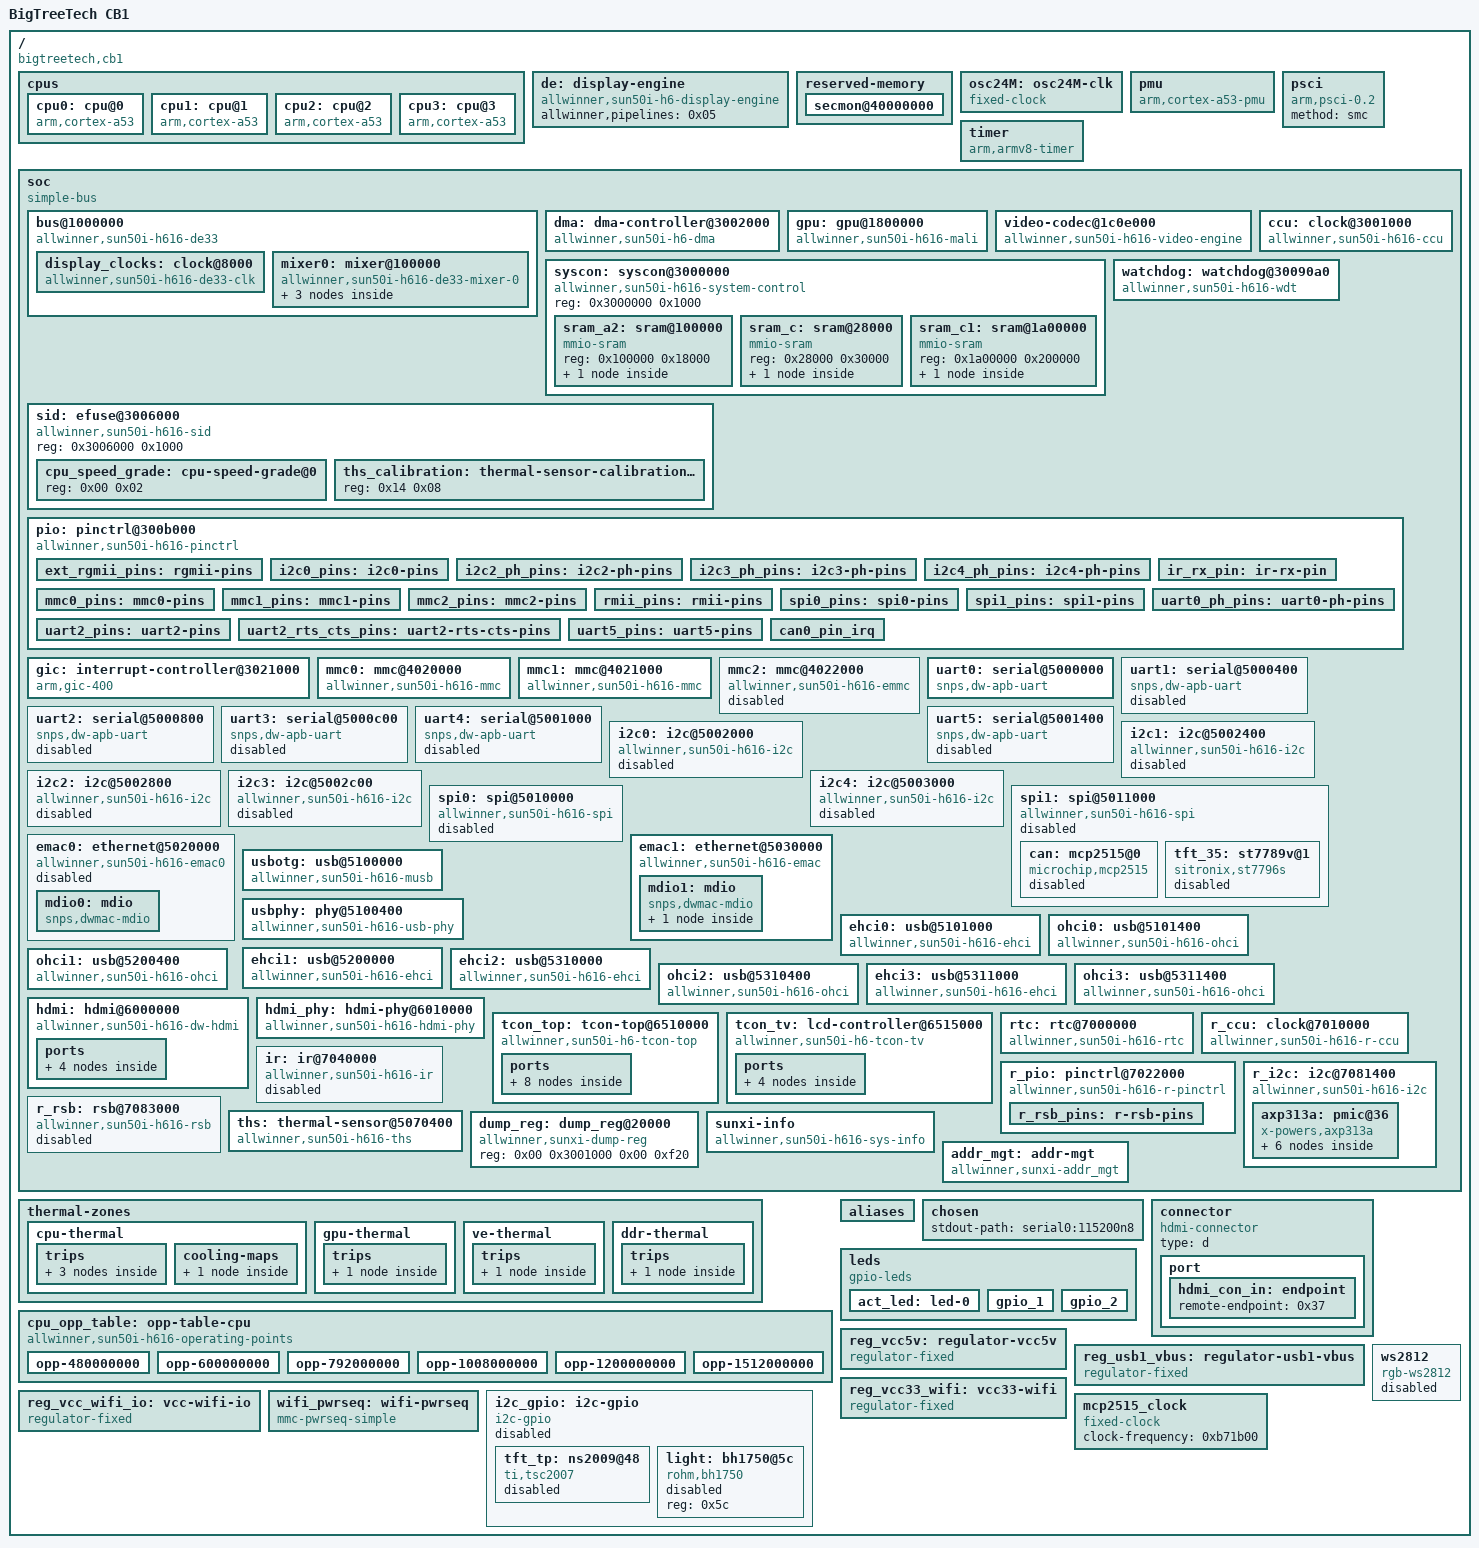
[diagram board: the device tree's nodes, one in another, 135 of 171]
/dts-v1/;

/ {
	interrupt-parent = <0x01>;
	#address-cells = <0x02>;
	#size-cells = <0x02>;
	model = "BigTreeTech CB1";
	compatible = "bigtreetech,cb1", "allwinner,sun50i-h616";

	cpus {
		#address-cells = <0x01>;
		#size-cells = <0x00>;

		cpu0: cpu@0 {
			compatible = "arm,cortex-a53";
			device_type = "cpu";
			reg = <0x00>;
			enable-method = "psci";
			clocks = <0x02 0x15>;
			clock-latency-ns = <0x3b9b0>;
			#cooling-cells = <0x02>;
			operating-points-v2 = <0x03>;
			cpu-supply = <0x04>;
			status = "okay";
			phandle = <0x06>;
		};

		cpu1: cpu@1 {
			compatible = "arm,cortex-a53";
			device_type = "cpu";
			reg = <0x01>;
			enable-method = "psci";
			clocks = <0x02 0x15>;
			clock-latency-ns = <0x3b9b0>;
			#cooling-cells = <0x02>;
			operating-points-v2 = <0x03>;
			phandle = <0x07>;
		};

		cpu2: cpu@2 {
			compatible = "arm,cortex-a53";
			device_type = "cpu";
			reg = <0x02>;
			enable-method = "psci";
			clocks = <0x02 0x15>;
			clock-latency-ns = <0x3b9b0>;
			#cooling-cells = <0x02>;
			operating-points-v2 = <0x03>;
			phandle = <0x08>;
		};

		cpu3: cpu@3 {
			compatible = "arm,cortex-a53";
			device_type = "cpu";
			reg = <0x03>;
			enable-method = "psci";
			clocks = <0x02 0x15>;
			clock-latency-ns = <0x3b9b0>;
			#cooling-cells = <0x02>;
			operating-points-v2 = <0x03>;
			phandle = <0x09>;
		};
	};

	de: display-engine {
		compatible = "allwinner,sun50i-h6-display-engine";
		allwinner,pipelines = <0x05>;
		status = "okay";
	};

	reserved-memory {
		#address-cells = <0x02>;
		#size-cells = <0x02>;
		ranges;

		secmon@40000000 {
			reg = <0x00 0x40000000 0x00 0x80000>;
			no-map;
		};
	};

	osc24M: osc24M-clk {
		#clock-cells = <0x00>;
		compatible = "fixed-clock";
		clock-frequency = <0x16e3600>;
		clock-output-names = "osc24M";
		phandle = <0x0f>;
	};

	pmu {
		compatible = "arm,cortex-a53-pmu";
		interrupts = <0x00 0x8c 0x04>, <0x00 0x8d 0x04>, <0x00 0x8e 0x04>, <0x00 0x8f 0x04>;
		interrupt-affinity = <0x06>, < 0x07>, < 0x08>, < 0x09>;
	};

	psci {
		compatible = "arm,psci-0.2";
		method = "smc";
	};

	timer {
		compatible = "arm,armv8-timer";
		arm,no-tick-in-suspend;
		interrupts = <0x01 0x0d 0xf04>, <0x01 0x0e 0xf04>, <0x01 0x0b 0xf04>, <0x01 0x0a 0xf04>;
	};

	soc {
		compatible = "simple-bus";
		#address-cells = <0x01>;
		#size-cells = <0x01>;
		ranges = <0x00 0x00 0x00 0x40000000>;

		bus@1000000 {
			compatible = "allwinner,sun50i-h616-de33", "allwinner,sun50i-a64-de2";
			reg = <0x1000000 0x400000>;
			allwinner,sram = <0x0a 0x01>;
			#address-cells = <0x01>;
			#size-cells = <0x01>;
			ranges = <0x00 0x1000000 0x400000>;

			display_clocks: clock@8000 {
				compatible = "allwinner,sun50i-h616-de33-clk";
				reg = <0x8000 0x100>;
				clocks = <0x02 0x1d>, < 0x02 0x1e>;
				clock-names = "mod", "bus";
				resets = <0x02 0x01>;
				#clock-cells = <0x01>;
				#reset-cells = <0x01>;
				phandle = <0x0b>;
			};

			mixer0: mixer@100000 {
				compatible = "allwinner,sun50i-h616-de33-mixer-0";
				reg = <0x100000 0x100000>, <0x8100 0x40>, <0x280000 0x20000>;
				clocks = <0x0b 0x00>, < 0x0b 0x06>;
				clock-names = "bus", "mod";
				resets = <0x0b 0x00>;
				phandle = <0x05>;

				ports {
					#address-cells = <0x01>;
					#size-cells = <0x00>;

					mixer0_out: port@1 {
						reg = <0x01>;

						mixer0_out_tcon_top_mixer0: endpoint {
							remote-endpoint = <0x0c>;
							phandle = <0x29>;
						};
					};
				};
			};
		};

		dma: dma-controller@3002000 {
			compatible = "allwinner,sun50i-h6-dma";
			reg = <0x3002000 0x1000>;
			interrupts = <0x00 0x2a 0x04>;
			clocks = <0x02 0x2a>, < 0x02 0x32>;
			clock-names = "bus", "mbus";
			dma-channels = <0x10>;
			dma-requests = <0x31>;
			resets = <0x02 0x06>;
			#dma-cells = <0x01>;
			phandle = <0x1a>;
		};

		gpu: gpu@1800000 {
			compatible = "allwinner,sun50i-h616-mali", "arm,mali-bifrost";
			reg = <0x1800000 0x40000>;
			interrupts = <0x00 0x5f 0x04>, <0x00 0x60 0x04>, <0x00 0x61 0x04>;
			interrupt-names = "job", "mmu", "gpu";
			clocks = <0x02 0x23>, < 0x02 0x24>;
			clock-names = "core", "bus";
			resets = <0x02 0x03>;
			status = "okay";
			mali-supply = <0x0d>;
		};

		video-codec@1c0e000 {
			compatible = "allwinner,sun50i-h616-video-engine";
			reg = <0x1c0e000 0x2000>;
			clocks = <0x02 0x29>, < 0x02 0x28>, < 0x02 0x33>;
			clock-names = "ahb", "mod", "ram";
			resets = <0x02 0x05>;
			interrupts = <0x00 0x5d 0x04>;
			allwinner,sram = <0x0e 0x01>;
		};

		syscon: syscon@3000000 {
			compatible = "allwinner,sun50i-h616-system-control";
			reg = <0x3000000 0x1000>;
			#address-cells = <0x01>;
			#size-cells = <0x01>;
			ranges;
			phandle = <0x20>;

			sram_a2: sram@100000 {
				compatible = "mmio-sram";
				reg = <0x100000 0x18000>;
				#address-cells = <0x01>;
				#size-cells = <0x01>;
				ranges = <0x00 0x100000 0x18000>;

				scpi_sram: scpi-sram@17c00 {
					compatible = "arm,scp-shmem";
					reg = <0x17c00 0x200>;
				};
			};

			sram_c: sram@28000 {
				compatible = "mmio-sram";
				reg = <0x28000 0x30000>;
				#address-cells = <0x01>;
				#size-cells = <0x01>;
				ranges = <0x00 0x28000 0x30000>;

				de3_sram: sram-section@0 {
					compatible = "allwinner,sun50i-h616-sram-c", "allwinner,sun50i-a64-sram-c";
					reg = <0x00 0x1e000>;
					phandle = <0x0a>;
				};
			};

			sram_c1: sram@1a00000 {
				compatible = "mmio-sram";
				reg = <0x1a00000 0x200000>;
				#address-cells = <0x01>;
				#size-cells = <0x01>;
				ranges = <0x00 0x1a00000 0x200000>;

				ve_sram: sram-section@0 {
					compatible = "allwinner,sun50i-h616-sram-c1";
					reg = <0x00 0x200000>;
					phandle = <0x0e>;
				};
			};
		};

		ccu: clock@3001000 {
			compatible = "allwinner,sun50i-h616-ccu";
			reg = <0x3001000 0x1000>;
			clocks = <0x0f>, < 0x10 0x00>, < 0x10 0x02>;
			clock-names = "hosc", "losc", "iosc";
			#clock-cells = <0x01>;
			#reset-cells = <0x01>;
			phandle = <0x02>;
		};

		sid: efuse@3006000 {
			compatible = "allwinner,sun50i-h616-sid";
			reg = <0x3006000 0x1000>;
			#address-cells = <0x01>;
			#size-cells = <0x01>;

			cpu_speed_grade: cpu-speed-grade@0 {
				reg = <0x00 0x02>;
				phandle = <0x36>;
			};

			ths_calibration: thermal-sensor-calibration@14 {
				reg = <0x14 0x08>;
				phandle = <0x33>;
			};
		};

		watchdog: watchdog@30090a0 {
			compatible = "allwinner,sun50i-h616-wdt", "allwinner,sun6i-a31-wdt";
			reg = <0x30090a0 0x20>;
			interrupts = <0x00 0x32 0x04>;
			clocks = <0x0f>;
		};

		pio: pinctrl@300b000 {
			compatible = "allwinner,sun50i-h616-pinctrl";
			reg = <0x300b000 0x400>;
			interrupts = <0x00 0x33 0x04>, <0x00 0x34 0x04>, <0x00 0x35 0x04>, <0x00 0x2b 0x04>, <0x00 0x36 0x04>, <0x00 0x37 0x04>, <0x00 0x38 0x04>, <0x00 0x39 0x04>;
			clocks = <0x02 0x1a>, < 0x0f>, < 0x10 0x00>;
			clock-names = "apb", "hosc", "losc";
			gpio-controller;
			#gpio-cells = <0x03>;
			interrupt-controller;
			#interrupt-cells = <0x03>;
			phandle = <0x1d>;

			ext_rgmii_pins: rgmii-pins {
				pins = "PI0", "PI1", "PI2", "PI3", "PI4", "PI5", "PI7", "PI8", "PI9", "PI10", "PI11", "PI12", "PI13", "PI14", "PI15", "PI16";
				function = "emac0";
				drive-strength = <0x28>;
			};

			i2c0_pins: i2c0-pins {
				pins = "PI6", "PI7";
				function = "i2c0";
				phandle = <0x19>;
			};

			i2c2_ph_pins: i2c2-ph-pins {
				pins = "PH2", "PH3";
				function = "i2c2";
			};

			i2c3_ph_pins: i2c3-ph-pins {
				pins = "PH4", "PH5";
				function = "i2c3";
			};

			i2c4_ph_pins: i2c4-ph-pins {
				pins = "PH6", "PH7";
				function = "i2c4";
			};

			ir_rx_pin: ir-rx-pin {
				pins = "PH10";
				function = "ir_rx";
				phandle = <0x31>;
			};

			mmc0_pins: mmc0-pins {
				pins = "PF0", "PF1", "PF2", "PF3", "PF4", "PF5";
				function = "mmc0";
				drive-strength = <0x1e>;
				bias-pull-up;
				phandle = <0x11>;
			};

			mmc1_pins: mmc1-pins {
				pins = "PG0", "PG1", "PG2", "PG3", "PG4", "PG5";
				function = "mmc1";
				drive-strength = <0x1e>;
				bias-pull-up;
				phandle = <0x13>;
			};

			mmc2_pins: mmc2-pins {
				pins = "PC0", "PC1", "PC5", "PC6", "PC8", "PC9", "PC10", "PC11", "PC13", "PC14", "PC15", "PC16";
				function = "mmc2";
				drive-strength = <0x1e>;
				bias-pull-up;
				phandle = <0x17>;
			};

			rmii_pins: rmii-pins {
				pins = "PA0", "PA1", "PA2", "PA3", "PA4", "PA5", "PA6", "PA7", "PA8", "PA9";
				function = "emac1";
				drive-strength = <0x28>;
				phandle = <0x21>;
			};

			spi0_pins: spi0-pins {
				pins = "PC0", "PC2", "PC4";
				function = "spi0";
				phandle = <0x1b>;
			};

			spi1_pins: spi1-pins {
				pins = "PH6", "PH7", "PH8";
				function = "spi1";
				phandle = <0x1c>;
			};

			uart0_ph_pins: uart0-ph-pins {
				pins = "PH0", "PH1";
				function = "uart0";
				phandle = <0x18>;
			};

			uart2_pins: uart2-pins {
				pins = "PH5", "PH6";
				function = "uart2";
			};

			uart2_rts_cts_pins: uart2-rts-cts-pins {
				pins = "PH7", "PH8";
				function = "uart2";
			};

			uart5_pins: uart5-pins {
				pins = "PH2", "PH3";
				function = "uart5";
			};

			can0_pin_irq: can0_pin_irq {
				function = "irq";
				bias-pull-up;
				pins = "PC9";
				phandle = <0x1f>;
			};
		};

		gic: interrupt-controller@3021000 {
			compatible = "arm,gic-400";
			reg = <0x3021000 0x1000>, <0x3022000 0x2000>, <0x3024000 0x2000>, <0x3026000 0x2000>;
			interrupts = <0x01 0x09 0xf04>;
			interrupt-controller;
			#interrupt-cells = <0x03>;
			phandle = <0x01>;
		};

		mmc0: mmc@4020000 {
			compatible = "allwinner,sun50i-h616-mmc", "allwinner,sun50i-a100-mmc";
			reg = <0x4020000 0x1000>;
			clocks = <0x02 0x3f>, < 0x02 0x3c>;
			clock-names = "ahb", "mmc";
			resets = <0x02 0x0e>;
			reset-names = "ahb";
			interrupts = <0x00 0x23 0x04>;
			pinctrl-names = "default";
			pinctrl-0 = <0x11>;
			status = "okay";
			max-frequency = <0x2faf080>;
			cap-sd-highspeed;
			cap-mmc-highspeed;
			mmc-ddr-3_3v;
			cap-sdio-irq;
			#address-cells = <0x01>;
			#size-cells = <0x00>;
			vmmc-supply = <0x12>;
			broken-cd;
			bus-width = <0x04>;
		};

		mmc1: mmc@4021000 {
			compatible = "allwinner,sun50i-h616-mmc", "allwinner,sun50i-a100-mmc";
			reg = <0x4021000 0x1000>;
			clocks = <0x02 0x40>, < 0x02 0x3d>;
			clock-names = "ahb", "mmc";
			resets = <0x02 0x0f>;
			reset-names = "ahb";
			interrupts = <0x00 0x24 0x04>;
			pinctrl-names = "default";
			pinctrl-0 = <0x13>;
			status = "okay";
			max-frequency = <0x17d7840>;
			cap-sd-highspeed;
			cap-mmc-highspeed;
			mmc-ddr-3_3v;
			cap-sdio-irq;
			#address-cells = <0x01>;
			#size-cells = <0x00>;
			vmmc-supply = <0x14>;
			vqmmc-supply = <0x15>;
			mmc-pwrseq = <0x16>;
			bus-width = <0x04>;
			non-removable;
			mmc-ddr-1_8v;
		};

		mmc2: mmc@4022000 {
			compatible = "allwinner,sun50i-h616-emmc", "allwinner,sun50i-a100-emmc";
			reg = <0x4022000 0x1000>;
			clocks = <0x02 0x41>, < 0x02 0x3e>;
			clock-names = "ahb", "mmc";
			resets = <0x02 0x10>;
			reset-names = "ahb";
			interrupts = <0x00 0x25 0x04>;
			pinctrl-names = "default";
			pinctrl-0 = <0x17>;
			status = "disabled";
			max-frequency = <0x8f0d180>;
			cap-sd-highspeed;
			cap-mmc-highspeed;
			mmc-ddr-3_3v;
			cap-sdio-irq;
			#address-cells = <0x01>;
			#size-cells = <0x00>;
		};

		uart0: serial@5000000 {
			compatible = "snps,dw-apb-uart";
			reg = <0x5000000 0x400>;
			interrupts = <0x00 0x00 0x04>;
			reg-shift = <0x02>;
			reg-io-width = <0x04>;
			clocks = <0x02 0x42>;
			resets = <0x02 0x11>;
			status = "okay";
			pinctrl-names = "default";
			pinctrl-0 = <0x18>;
		};

		uart1: serial@5000400 {
			compatible = "snps,dw-apb-uart";
			reg = <0x5000400 0x400>;
			interrupts = <0x00 0x01 0x04>;
			reg-shift = <0x02>;
			reg-io-width = <0x04>;
			clocks = <0x02 0x43>;
			resets = <0x02 0x12>;
			status = "disabled";
		};

		uart2: serial@5000800 {
			compatible = "snps,dw-apb-uart";
			reg = <0x5000800 0x400>;
			interrupts = <0x00 0x02 0x04>;
			reg-shift = <0x02>;
			reg-io-width = <0x04>;
			clocks = <0x02 0x44>;
			resets = <0x02 0x13>;
			status = "disabled";
		};

		uart3: serial@5000c00 {
			compatible = "snps,dw-apb-uart";
			reg = <0x5000c00 0x400>;
			interrupts = <0x00 0x03 0x04>;
			reg-shift = <0x02>;
			reg-io-width = <0x04>;
			clocks = <0x02 0x45>;
			resets = <0x02 0x14>;
			status = "disabled";
		};

		uart4: serial@5001000 {
			compatible = "snps,dw-apb-uart";
			reg = <0x5001000 0x400>;
			interrupts = <0x00 0x04 0x04>;
			reg-shift = <0x02>;
			reg-io-width = <0x04>;
			clocks = <0x02 0x46>;
			resets = <0x02 0x15>;
			status = "disabled";
		};

		uart5: serial@5001400 {
			compatible = "snps,dw-apb-uart";
			reg = <0x5001400 0x400>;
			interrupts = <0x00 0x05 0x04>;
			reg-shift = <0x02>;
			reg-io-width = <0x04>;
			clocks = <0x02 0x47>;
			resets = <0x02 0x16>;
			status = "disabled";
		};

		i2c0: i2c@5002000 {
			compatible = "allwinner,sun50i-h616-i2c", "allwinner,sun8i-v536-i2c", "allwinner,sun6i-a31-i2c";
			reg = <0x5002000 0x400>;
			interrupts = <0x00 0x06 0x04>;
			clocks = <0x02 0x48>;
			resets = <0x02 0x17>;
			pinctrl-names = "default";
			pinctrl-0 = <0x19>;
			status = "disabled";
			#address-cells = <0x01>;
			#size-cells = <0x00>;
		};

		i2c1: i2c@5002400 {
			compatible = "allwinner,sun50i-h616-i2c", "allwinner,sun8i-v536-i2c", "allwinner,sun6i-a31-i2c";
			reg = <0x5002400 0x400>;
			interrupts = <0x00 0x07 0x04>;
			clocks = <0x02 0x49>;
			resets = <0x02 0x18>;
			status = "disabled";
			#address-cells = <0x01>;
			#size-cells = <0x00>;
		};

		i2c2: i2c@5002800 {
			compatible = "allwinner,sun50i-h616-i2c", "allwinner,sun8i-v536-i2c", "allwinner,sun6i-a31-i2c";
			reg = <0x5002800 0x400>;
			interrupts = <0x00 0x08 0x04>;
			clocks = <0x02 0x4a>;
			resets = <0x02 0x19>;
			status = "disabled";
			#address-cells = <0x01>;
			#size-cells = <0x00>;
		};

		i2c3: i2c@5002c00 {
			compatible = "allwinner,sun50i-h616-i2c", "allwinner,sun8i-v536-i2c", "allwinner,sun6i-a31-i2c";
			reg = <0x5002c00 0x400>;
			interrupts = <0x00 0x09 0x04>;
			clocks = <0x02 0x4b>;
			resets = <0x02 0x1a>;
			status = "disabled";
			#address-cells = <0x01>;
			#size-cells = <0x00>;
		};

		i2c4: i2c@5003000 {
			compatible = "allwinner,sun50i-h616-i2c", "allwinner,sun8i-v536-i2c", "allwinner,sun6i-a31-i2c";
			reg = <0x5003000 0x400>;
			interrupts = <0x00 0x0a 0x04>;
			clocks = <0x02 0x4c>;
			resets = <0x02 0x1b>;
			status = "disabled";
			#address-cells = <0x01>;
			#size-cells = <0x00>;
		};

		spi0: spi@5010000 {
			compatible = "allwinner,sun50i-h616-spi", "allwinner,sun8i-h3-spi";
			reg = <0x5010000 0x1000>;
			interrupts = <0x00 0x0c 0x04>;
			clocks = <0x02 0x4f>, < 0x02 0x4d>;
			clock-names = "ahb", "mod";
			dmas = <0x1a 0x16>, < 0x1a 0x16>;
			dma-names = "rx", "tx";
			resets = <0x02 0x1c>;
			pinctrl-names = "default";
			pinctrl-0 = <0x1b>;
			status = "disabled";
			#address-cells = <0x01>;
			#size-cells = <0x00>;
		};

		spi1: spi@5011000 {
			compatible = "allwinner,sun50i-h616-spi", "allwinner,sun8i-h3-spi";
			reg = <0x5011000 0x1000>;
			interrupts = <0x00 0x0d 0x04>;
			clocks = <0x02 0x50>, < 0x02 0x4e>;
			clock-names = "ahb", "mod";
			dmas = <0x1a 0x17>, < 0x1a 0x17>;
			dma-names = "rx", "tx";
			resets = <0x02 0x1d>;
			pinctrl-names = "default";
			pinctrl-0 = <0x1c>;
			status = "disabled";
			#address-cells = <0x01>;
			#size-cells = <0x00>;
			cs-gpios = <0x1d 0x02 0x0b 0x00>, < 0x1d 0x02 0x07 0x00>, < 0x1d 0x02 0x0d 0x00>;

			can: mcp2515@0 {
				status = "disabled";
				compatible = "microchip,mcp2515";
				reg = <0x00>;
				clocks = <0x1e>;
				spi-max-frequency = <0xbebc20>;
				pinctrl-names = "default";
				pinctrl-0 = <0x1f>;
				interrupt-parent = <0x1d>;
				vdd-supply = <0x14>;
				xceiver-supply = <0x14>;
				interrupts = <0x02 0x09 0x08>;
			};

			tft_35: st7789v@1 {
				status = "disabled";
				compatible = "sitronix,st7796s";
				reg = <0x01>;
				spi-max-frequency = <0xbebc20>;
				fps = <0x3c>;
				buswidth = <0x08>;
				rotate = <0x00>;
				width = <0x1e0>;
				height = <0x140>;
				bpp = <0x18>;
				bgr;
				regwidth = <0x08>;
				debug = <0x00>;
				txbuflen = <0x4b000>;
				spi-cpol;
				spi-cpha;
				dc-gpios = <0x1d 0x02 0x0e 0x00>;
			};
		};

		emac0: ethernet@5020000 {
			compatible = "allwinner,sun50i-h616-emac0", "allwinner,sun50i-a64-emac";
			reg = <0x5020000 0x10000>;
			interrupts = <0x00 0x0e 0x04>;
			interrupt-names = "macirq";
			clocks = <0x02 0x52>;
			clock-names = "stmmaceth";
			resets = <0x02 0x1e>;
			reset-names = "stmmaceth";
			syscon = <0x20>;
			status = "disabled";

			mdio0: mdio {
				compatible = "snps,dwmac-mdio";
				#address-cells = <0x01>;
				#size-cells = <0x00>;
			};
		};

		emac1: ethernet@5030000 {
			compatible = "allwinner,sun50i-h616-emac";
			syscon = <0x20 0x01>;
			reg = <0x5030000 0x10000>;
			interrupts = <0x00 0x0f 0x04>;
			interrupt-names = "macirq";
			resets = <0x02 0x1f>;
			reset-names = "stmmaceth";
			clocks = <0x02 0x53>;
			clock-names = "stmmaceth";
			status = "okay";
			pinctrl-names = "default";
			pinctrl-0 = <0x21>;
			phy-mode = "rmii";
			phy-handle = <0x22>;
			phy-supply = <0x12>;
			allwinner,rx-delay-ps = <0xc1c>;
			allwinner,tx-delay-ps = <0x2bc>;

			mdio1: mdio {
				compatible = "snps,dwmac-mdio";
				#address-cells = <0x01>;
				#size-cells = <0x00>;

				rmii_phy: ethernet-phy@1 {
					compatible = "ethernet-phy-ieee802.3-c22";
					reg = <0x01>;
					phandle = <0x22>;
				};
			};
		};

		usbotg: usb@5100000 {
			compatible = "allwinner,sun50i-h616-musb", "allwinner,sun8i-h3-musb";
			reg = <0x5100000 0x400>;
			clocks = <0x02 0x70>;
			resets = <0x02 0x32>;
			interrupts = <0x00 0x19 0x04>;
			interrupt-names = "mc";
			phys = <0x23 0x00>;
			phy-names = "usb";
			extcon = <0x23 0x00>;
			status = "okay";
			dr_mode = "peripheral";
		};

		usbphy: phy@5100400 {
			compatible = "allwinner,sun50i-h616-usb-phy";
			reg = <0x5100400 0x24>, <0x5101800 0x14>, <0x5200800 0x14>, <0x5310800 0x14>, <0x5311800 0x14>;
			reg-names = "phy_ctrl", "pmu0", "pmu1", "pmu2", "pmu3";
			clocks = <0x02 0x61>, < 0x02 0x63>, < 0x02 0x65>, < 0x02 0x67>, < 0x02 0x6e>;
			clock-names = "usb0_phy", "usb1_phy", "usb2_phy", "usb3_phy", "pmu2_clk";
			resets = <0x02 0x26>, < 0x02 0x27>, < 0x02 0x28>, < 0x02 0x29>;
			reset-names = "usb0_reset", "usb1_reset", "usb2_reset", "usb3_reset";
			status = "okay";
			#phy-cells = <0x01>;
			usb1_vbus-supply = <0x24>;
			phandle = <0x23>;
		};

		ehci0: usb@5101000 {
			compatible = "allwinner,sun50i-h616-ehci", "generic-ehci";
			reg = <0x5101000 0x100>;
			interrupts = <0x00 0x1a 0x04>;
			clocks = <0x02 0x68>, < 0x02 0x6c>, < 0x02 0x60>;
			resets = <0x02 0x2a>, < 0x02 0x2e>;
			phys = <0x23 0x00>;
			phy-names = "usb";
			status = "okay";
		};

		ohci0: usb@5101400 {
			compatible = "allwinner,sun50i-h616-ohci", "generic-ohci";
			reg = <0x5101400 0x100>;
			interrupts = <0x00 0x1b 0x04>;
			clocks = <0x02 0x68>, < 0x02 0x60>;
			resets = <0x02 0x2a>;
			phys = <0x23 0x00>;
			phy-names = "usb";
			status = "okay";
		};

		ehci1: usb@5200000 {
			compatible = "allwinner,sun50i-h616-ehci", "generic-ehci";
			reg = <0x5200000 0x100>;
			interrupts = <0x00 0x1c 0x04>;
			clocks = <0x02 0x69>, < 0x02 0x6d>, < 0x02 0x62>;
			resets = <0x02 0x2b>, < 0x02 0x2f>;
			phys = <0x23 0x01>;
			phy-names = "usb";
			status = "okay";
		};

		ohci1: usb@5200400 {
			compatible = "allwinner,sun50i-h616-ohci", "generic-ohci";
			reg = <0x5200400 0x100>;
			interrupts = <0x00 0x1d 0x04>;
			clocks = <0x02 0x69>, < 0x02 0x62>;
			resets = <0x02 0x2b>;
			phys = <0x23 0x01>;
			phy-names = "usb";
			status = "okay";
		};

		ehci2: usb@5310000 {
			compatible = "allwinner,sun50i-h616-ehci", "generic-ehci";
			reg = <0x5310000 0x100>;
			interrupts = <0x00 0x1e 0x04>;
			clocks = <0x02 0x6a>, < 0x02 0x6e>, < 0x02 0x64>;
			resets = <0x02 0x2c>, < 0x02 0x30>;
			phys = <0x23 0x02>;
			phy-names = "usb";
			status = "okay";
		};

		ohci2: usb@5310400 {
			compatible = "allwinner,sun50i-h616-ohci", "generic-ohci";
			reg = <0x5310400 0x100>;
			interrupts = <0x00 0x1f 0x04>;
			clocks = <0x02 0x6a>, < 0x02 0x64>;
			resets = <0x02 0x2c>;
			phys = <0x23 0x02>;
			phy-names = "usb";
			status = "okay";
		};

		ehci3: usb@5311000 {
			compatible = "allwinner,sun50i-h616-ehci", "generic-ehci";
			reg = <0x5311000 0x100>;
			interrupts = <0x00 0x20 0x04>;
			clocks = <0x02 0x6b>, < 0x02 0x6f>, < 0x02 0x66>;
			resets = <0x02 0x2d>, < 0x02 0x31>;
			phys = <0x23 0x03>;
			phy-names = "usb";
			status = "okay";
		};

		ohci3: usb@5311400 {
			compatible = "allwinner,sun50i-h616-ohci", "generic-ohci";
			reg = <0x5311400 0x100>;
			interrupts = <0x00 0x21 0x04>;
			clocks = <0x02 0x6b>, < 0x02 0x66>;
			resets = <0x02 0x2d>;
			phys = <0x23 0x03>;
			phy-names = "usb";
			status = "okay";
		};

		hdmi: hdmi@6000000 {
			#sound-dai-cells = <0x00>;
			compatible = "allwinner,sun50i-h616-dw-hdmi", "allwinner,sun50i-h6-dw-hdmi";
			reg = <0x6000000 0x10000>;
			reg-io-width = <0x01>;
			interrupts = <0x00 0x3f 0x04>;
			clocks = <0x02 0x75>, < 0x02 0x73>, < 0x02 0x72>, < 0x02 0x74>, < 0x02 0x7e>, < 0x02 0x7f>;
			clock-names = "iahb", "isfr", "tmds", "cec", "hdcp", "hdcp-bus";
			resets = <0x02 0x33>, < 0x02 0x3a>;
			reset-names = "ctrl", "hdcp";
			phys = <0x25>;
			phy-names = "phy";
			status = "okay";
			hvcc-supply = <0x26>;

			ports {
				#address-cells = <0x01>;
				#size-cells = <0x00>;

				hdmi_in: port@0 {
					reg = <0x00>;

					hdmi_in_tcon_top: endpoint {
						remote-endpoint = <0x27>;
						phandle = <0x2c>;
					};
				};

				hdmi_out: port@1 {
					reg = <0x01>;

					hdmi_out_con: endpoint {
						remote-endpoint = <0x28>;
						phandle = <0x37>;
					};
				};
			};
		};

		hdmi_phy: hdmi-phy@6010000 {
			compatible = "allwinner,sun50i-h616-hdmi-phy";
			reg = <0x6010000 0x10000>;
			clocks = <0x02 0x75>, < 0x02 0x73>;
			clock-names = "bus", "mod";
			resets = <0x02 0x34>;
			reset-names = "phy";
			#phy-cells = <0x00>;
			phandle = <0x25>;
		};

		tcon_top: tcon-top@6510000 {
			compatible = "allwinner,sun50i-h6-tcon-top";
			reg = <0x6510000 0x1000>;
			clocks = <0x02 0x76>, < 0x02 0x77>;
			clock-names = "bus", "tcon-tv0";
			clock-output-names = "tcon-top-tv0";
			resets = <0x02 0x35>;
			#clock-cells = <0x01>;
			phandle = <0x2d>;

			ports {
				#address-cells = <0x01>;
				#size-cells = <0x00>;

				tcon_top_mixer0_in: port@0 {
					#address-cells = <0x01>;
					#size-cells = <0x00>;
					reg = <0x00>;

					tcon_top_mixer0_in_mixer0: endpoint@0 {
						reg = <0x00>;
						remote-endpoint = <0x29>;
						phandle = <0x0c>;
					};
				};

				tcon_top_mixer0_out: port@1 {
					#address-cells = <0x01>;
					#size-cells = <0x00>;
					reg = <0x01>;

					tcon_top_mixer0_out_tcon_tv: endpoint@2 {
						reg = <0x02>;
						remote-endpoint = <0x2a>;
						phandle = <0x2e>;
					};
				};

				tcon_top_hdmi_in: port@4 {
					#address-cells = <0x01>;
					#size-cells = <0x00>;
					reg = <0x04>;

					tcon_top_hdmi_in_tcon_tv: endpoint@0 {
						reg = <0x00>;
						remote-endpoint = <0x2b>;
						phandle = <0x2f>;
					};
				};

				tcon_top_hdmi_out: port@5 {
					reg = <0x05>;

					tcon_top_hdmi_out_hdmi: endpoint {
						remote-endpoint = <0x2c>;
						phandle = <0x27>;
					};
				};
			};
		};

		tcon_tv: lcd-controller@6515000 {
			compatible = "allwinner,sun50i-h6-tcon-tv", "allwinner,sun8i-r40-tcon-tv";
			reg = <0x6515000 0x1000>;
			interrupts = <0x00 0x42 0x04>;
			clocks = <0x02 0x79>, < 0x2d 0x00>;
			clock-names = "ahb", "tcon-ch1";
			resets = <0x02 0x36>;
			reset-names = "lcd";

			ports {
				#address-cells = <0x01>;
				#size-cells = <0x00>;

				tcon_tv_in: port@0 {
					reg = <0x00>;

					tcon_tv_in_tcon_top_mixer0: endpoint {
						remote-endpoint = <0x2e>;
						phandle = <0x2a>;
					};
				};

				tcon_tv_out: port@1 {
					#address-cells = <0x01>;
					#size-cells = <0x00>;
					reg = <0x01>;

					tcon_tv_out_tcon_top: endpoint@1 {
						reg = <0x01>;
						remote-endpoint = <0x2f>;
						phandle = <0x2b>;
					};
				};
			};
		};

		rtc: rtc@7000000 {
			compatible = "allwinner,sun50i-h616-rtc";
			reg = <0x7000000 0x400>;
			interrupts = <0x00 0x68 0x04>;
			clocks = <0x30 0x0e>, < 0x0f>, < 0x02 0x80>;
			clock-names = "bus", "hosc", "pll-32k";
			#clock-cells = <0x01>;
			phandle = <0x10>;
		};

		r_ccu: clock@7010000 {
			compatible = "allwinner,sun50i-h616-r-ccu";
			reg = <0x7010000 0x210>;
			clocks = <0x0f>, < 0x10 0x00>, < 0x10 0x02>, < 0x02 0x04>;
			clock-names = "hosc", "losc", "iosc", "pll-periph";
			#clock-cells = <0x01>;
			#reset-cells = <0x01>;
			phandle = <0x30>;
		};

		r_pio: pinctrl@7022000 {
			compatible = "allwinner,sun50i-h616-r-pinctrl";
			reg = <0x7022000 0x400>;
			interrupts = <0x00 0x8f 0x04>;
			clocks = <0x30 0x02>, < 0x0f>, < 0x10 0x00>;
			clock-names = "apb", "hosc", "losc";
			gpio-controller;
			#gpio-cells = <0x03>;
			interrupt-controller;
			#interrupt-cells = <0x03>;

			r_rsb_pins: r-rsb-pins {
				pins = "PL0", "PL1";
				function = "s_rsb";
				phandle = <0x32>;
			};
		};

		ir: ir@7040000 {
			compatible = "allwinner,sun50i-h616-ir", "allwinner,sun6i-a31-ir";
			reg = <0x7040000 0x400>;
			interrupts = <0x00 0x6a 0x04>;
			clocks = <0x30 0x09>, < 0x30 0x0b>;
			clock-names = "apb", "ir";
			resets = <0x30 0x05>;
			pinctrl-names = "default";
			pinctrl-0 = <0x31>;
			status = "disabled";
		};

		r_i2c: i2c@7081400 {
			compatible = "allwinner,sun50i-h616-i2c", "allwinner,sun8i-v536-i2c", "allwinner,sun6i-a31-i2c";
			reg = <0x7081400 0x400>;
			interrupts = <0x00 0x69 0x04>;
			clocks = <0x30 0x08>;
			resets = <0x30 0x04>;
			status = "okay";
			#address-cells = <0x01>;
			#size-cells = <0x00>;

			axp313a: pmic@36 {
				compatible = "x-powers,axp313a";
				reg = <0x36>;
				wakeup-source;

				regulators {

					reg_dcdc1: dcdc1 {
						regulator-name = "axp313a-dcdc1";
						regulator-min-microvolt = <0x7a120>;
						regulator-max-microvolt = <0x33e140>;
						regulator-step-delay-us = <0x19>;
						regulator-final-delay-us = <0x32>;
						regulator-always-on;
					};

					reg_dcdc2: dcdc2 {
						regulator-name = "axp313a-dcdc2";
						regulator-min-microvolt = <0x7a120>;
						regulator-max-microvolt = <0x177fa0>;
						regulator-step-delay-us = <0x19>;
						regulator-final-delay-us = <0x32>;
						regulator-ramp-delay = <0xc8>;
						regulator-always-on;
						phandle = <0x04>;
					};

					reg_dcdc3: dcdc3 {
						regulator-name = "axp313a-dcdc3";
						regulator-min-microvolt = <0x7a120>;
						regulator-max-microvolt = <0x1c1380>;
						regulator-step-delay-us = <0x19>;
						regulator-final-delay-us = <0x32>;
						regulator-always-on;
						phandle = <0x0d>;
					};

					reg_aldo1: aldo1 {
						regulator-name = "axp313a-aldo1";
						regulator-min-microvolt = <0x1b7740>;
						regulator-max-microvolt = <0x1b7740>;
						regulator-step-delay-us = <0x19>;
						regulator-final-delay-us = <0x32>;
						regulator-always-on;
						phandle = <0x26>;
					};

					reg_dldo1: dldo1 {
						regulator-name = "axp313a-dldo1";
						regulator-min-microvolt = <0x325aa0>;
						regulator-max-microvolt = <0x325aa0>;
						regulator-step-delay-us = <0x19>;
						regulator-final-delay-us = <0x32>;
						regulator-always-on;
						phandle = <0x12>;
					};
				};
			};
		};

		r_rsb: rsb@7083000 {
			compatible = "allwinner,sun50i-h616-rsb", "allwinner,sun8i-a23-rsb";
			reg = <0x7083000 0x400>;
			interrupts = <0x00 0x6d 0x04>;
			clocks = <0x30 0x0d>;
			clock-frequency = <0x2dc6c0>;
			resets = <0x30 0x07>;
			pinctrl-names = "default";
			pinctrl-0 = <0x32>;
			status = "disabled";
			#address-cells = <0x01>;
			#size-cells = <0x00>;
		};

		ths: thermal-sensor@5070400 {
			compatible = "allwinner,sun50i-h616-ths";
			reg = <0x5070400 0x400>;
			interrupts = <0x00 0x13 0x04>;
			clocks = <0x02 0x56>;
			clock-names = "bus";
			resets = <0x02 0x21>;
			nvmem-cells = <0x33>;
			nvmem-cell-names = "calibration";
			#thermal-sensor-cells = <0x01>;
			phandle = <0x34>;
		};

		dump_reg: dump_reg@20000 {
			compatible = "allwinner,sunxi-dump-reg";
			reg = <0x00 0x3001000 0x00 0xf20>;
			status = "okay";
		};

		sunxi-info {
			compatible = "allwinner,sun50i-h616-sys-info";
			status = "okay";
		};

		addr_mgt: addr-mgt {
			compatible = "allwinner,sunxi-addr_mgt";
			type_addr_wifi = <0x02>;
			type_addr_bt = <0x02>;
			type_addr_eth = <0x02>;
			status = "okay";
		};
	};

	thermal-zones {

		cpu-thermal {
			polling-delay-passive = <0x1f4>;
			polling-delay = <0x3e8>;
			thermal-sensors = <0x34 0x02>;
			sustainable-power = <0x3e8>;
			k_po = <0x14>;
			k_pu = <0x28>;
			k_i = <0x00>;

			trips {

				cpu_threshold: trip-point@0 {
					temperature = <0xea60>;
					type = "passive";
					hysteresis = <0x00>;
				};

				cpu_target: trip-point@1 {
					temperature = <0x11170>;
					type = "passive";
					hysteresis = <0x00>;
					phandle = <0x35>;
				};

				cpu_temp_critical: trip-point@2 {
					temperature = <0x1adb0>;
					type = "critical";
					hysteresis = <0x00>;
				};
			};

			cooling-maps {

				map0 {
					trip = <0x35>;
					cooling-device = <0x06 0xffffffff 0xffffffff>, < 0x07 0xffffffff 0xffffffff>, < 0x08 0xffffffff 0xffffffff>, < 0x09 0xffffffff 0xffffffff>;
				};
			};
		};

		gpu-thermal {
			polling-delay-passive = <0x1f4>;
			polling-delay = <0x3e8>;
			thermal-sensors = <0x34 0x00>;
			sustainable-power = <0x44c>;

			trips {

				gpu_temp_critical: trip-point@0 {
					temperature = <0x1adb0>;
					type = "critical";
					hysteresis = <0x00>;
				};
			};
		};

		ve-thermal {
			polling-delay-passive = <0x00>;
			polling-delay = <0x00>;
			thermal-sensors = <0x34 0x01>;

			trips {

				ve_temp_critical: trip-point@0 {
					temperature = <0x1adb0>;
					type = "critical";
					hysteresis = <0x00>;
				};
			};
		};

		ddr-thermal {
			polling-delay-passive = <0x00>;
			polling-delay = <0x00>;
			thermal-sensors = <0x34 0x03>;

			trips {

				ddr_temp_critical: trip-point@0 {
					temperature = <0x1adb0>;
					type = "critical";
					hysteresis = <0x00>;
				};
			};
		};
	};

	cpu_opp_table: opp-table-cpu {
		compatible = "allwinner,sun50i-h616-operating-points";
		nvmem-cells = <0x36>;
		opp-shared;
		phandle = <0x03>;

		opp-480000000 {
			clock-latency-ns = <0x3b9b0>;
			opp-hz = /bits/ 64 <0x1c9c3800>;
			opp-microvolt-speed0 = <0xc8320 0xc8320 0x10c8e0>;
			opp-microvolt-speed1 = <0xd6d80 0xd6d80 0x10c8e0>;
			opp-microvolt-speed2 = <0xd6d80 0xd6d80 0x10c8e0>;
		};

		opp-600000000 {
			clock-latency-ns = <0x3b9b0>;
			opp-hz = /bits/ 64 <0x23c34600>;
			opp-microvolt-speed0 = <0xc8320 0xc8320 0x10c8e0>;
			opp-microvolt-speed1 = <0xd6d80 0xd6d80 0x10c8e0>;
			opp-microvolt-speed2 = <0xd6d80 0xd6d80 0x10c8e0>;
		};

		opp-792000000 {
			clock-latency-ns = <0x3b9b0>;
			opp-hz = /bits/ 64 <0x2f34f600>;
			opp-microvolt-speed0 = <0xd1f60 0xd1f60 0x10c8e0>;
			opp-microvolt-speed1 = <0xe57e0 0xe57e0 0x10c8e0>;
			opp-microvolt-speed2 = <0xe57e0 0xe57e0 0x10c8e0>;
		};

		opp-1008000000 {
			clock-latency-ns = <0x3b9b0>;
			opp-hz = /bits/ 64 <0x3c14dc00>;
			opp-microvolt-speed0 = <0xdbba0 0xdbba0 0x10c8e0>;
			opp-microvolt-speed1 = <0xf9060 0xf9060 0x10c8e0>;
			opp-microvolt-speed2 = <0xf9060 0xf9060 0x10c8e0>;
		};

		opp-1200000000 {
			clock-latency-ns = <0x3b9b0>;
			opp-hz = /bits/ 64 <0x47868c00>;
			opp-microvolt-speed0 = <0xea600 0xea600 0x10c8e0>;
			opp-microvolt-speed1 = <0x10c8e0 0x10c8e0 0x10c8e0>;
			opp-microvolt-speed2 = <0x10c8e0 0x10c8e0 0x10c8e0>;
		};

		opp-1512000000 {
			clock-latency-ns = <0x3b9b0>;
			opp-hz = /bits/ 64 <0x5a1f4a00>;
			opp-microvolt-speed0 = <0x10c8e0 0x10c8e0 0x10c8e0>;
			opp-microvolt-speed1 = <0x10c8e0 0x10c8e0 0x10c8e0>;
			opp-microvolt-speed2 = <0x10c8e0 0x10c8e0 0x10c8e0>;
		};
	};

	aliases {
		ethernet0 = "/soc/ethernet@5030000";
		serial0 = "/soc/serial@5000000";
	};

	chosen {
		stdout-path = "serial0:115200n8";
	};

	connector {
		compatible = "hdmi-connector";
		type = "d";

		port {

			hdmi_con_in: endpoint {
				remote-endpoint = <0x37>;
				phandle = <0x28>;
			};
		};
	};

	leds {
		compatible = "gpio-leds";

		act_led: led-0 {
			gpios = <0x1d 0x07 0x05 0x01>;
			linux,default-trigger = "heartbeat";
		};

		gpio_1 {
			function = "wifi_power";
			gpios = <0x1d 0x05 0x06 0x00>;
			default-state = "on";
		};

		gpio_2 {
			function = "wifi_wake";
			gpios = <0x1d 0x06 0x0f 0x00>;
			default-state = "on";
		};
	};

	reg_vcc5v: regulator-vcc5v {
		compatible = "regulator-fixed";
		regulator-name = "vcc-5v";
		regulator-min-microvolt = <0x4c4b40>;
		regulator-max-microvolt = <0x4c4b40>;
		regulator-always-on;
		phandle = <0x38>;
	};

	reg_usb1_vbus: regulator-usb1-vbus {
		compatible = "regulator-fixed";
		regulator-name = "usb1-vbus";
		regulator-min-microvolt = <0x4c4b40>;
		regulator-max-microvolt = <0x4c4b40>;
		vin-supply = <0x38>;
		enable-active-high;
		phandle = <0x24>;
	};

	reg_vcc33_wifi: vcc33-wifi {
		compatible = "regulator-fixed";
		regulator-name = "vcc33-wifi";
		regulator-min-microvolt = <0x325aa0>;
		regulator-max-microvolt = <0x325aa0>;
		regulator-always-on;
		vin-supply = <0x38>;
		phandle = <0x14>;
	};

	reg_vcc_wifi_io: vcc-wifi-io {
		compatible = "regulator-fixed";
		regulator-name = "vcc-wifi-io";
		regulator-min-microvolt = <0x1b7740>;
		regulator-max-microvolt = <0x1b7740>;
		regulator-always-on;
		vin-supply = <0x14>;
		phandle = <0x15>;
	};

	wifi_pwrseq: wifi-pwrseq {
		compatible = "mmc-pwrseq-simple";
		clocks = <0x10 0x01>;
		clock-names = "osc32k-out";
		reset-gpios = <0x1d 0x06 0x12 0x01>;
		post-power-on-delay-ms = <0xc8>;
		phandle = <0x16>;
	};

	ws2812: ws2812 {
		compatible = "rgb-ws2812";
		pinctrl-names = "default";
		rgb_cnt = <0x02>;
		rgb_value = <0x10000 0x10000>;
		status = "disabled";
		gpios = <0x1d 0x02 0x0e 0x01>;
	};

	i2c_gpio: i2c-gpio {
		#address-cells = <0x01>;
		#size-cells = <0x00>;
		compatible = "i2c-gpio";
		status = "disabled";
		i2c-gpio,delay-us = <0x03>;
		gpios = <0x1d 0x02 0x0c 0x00>, < 0x1d 0x02 0x0a 0x00>;

		tft_tp: ns2009@48 {
			compatible = "ti,tsc2007";
			reg = <0x48>;
			status = "disabled";
			ti,x-plate-ohms = <0x294>;
			ti,rt-thr = <0xbb8>;
			ti,fuzzx = <0x20>;
			ti,fuzzy = <0x10>;
			i2c,ignore-nak = <0x01>;
		};

		light: bh1750@5c {
			compatible = "rohm,bh1750";
			reg = <0x5c>;
			status = "disabled";
		};
	};

	mcp2515_clock: mcp2515_clock {
		compatible = "fixed-clock";
		#clock-cells = <0x00>;
		clock-frequency = <0xb71b00>;
		phandle = <0x1e>;
	};
};
